# STM32C593 register map
File version: 2.1.0
CPU: CM33 r0p4, little endian, MPU, FPU, 4 interrupt priority bits
Registers are 32-bit, read-write, reset 0x0 unless marked. A register's access mark holds for its fields unless they carry their own. Offsets are from the block's base; [hi:lo] are bit positions; {n}, {i} and the like mark numbered series; 'fields as' and 'values as' point back to an identical list.

## EXTI — EXTI address block description
Base 0x44022000
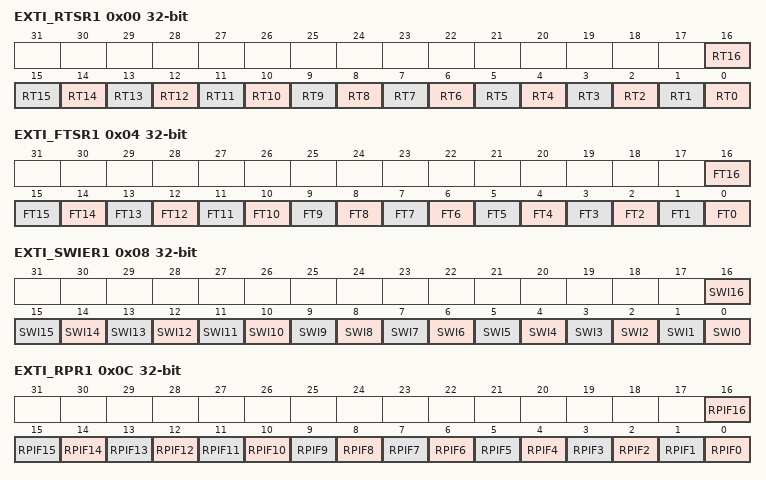
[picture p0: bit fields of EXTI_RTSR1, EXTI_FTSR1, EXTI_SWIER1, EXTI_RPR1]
0x00 EXTI_RTSR1 — EXTI rising trigger selection register
  [all] fields
    0=Rising trigger disabled (for event and interrupt) for input line; 1=Rising trigger enabled (for event and interrupt) for input line
  [n] RT{n} (n=0..16) — Rising trigger event configuration bit of configurable event input x
0x04 EXTI_FTSR1 — EXTI falling trigger selection register
  [all] fields
    0=Falling trigger disabled (for event and Interrupt) for input line; 1=Falling trigger enabled (for event and Interrupt) for input line
  [n] FT{n} (n=0..16) — Falling trigger event configuration bit of configurable event input x
0x08 EXTI_SWIER1 — EXTI software interrupt event register
  [all] fields
    0=Writing 0 has no effect; 1=Writing 1 triggers a rising edge event on event x
  [n] SWI{n} (n=0..16) — Software interrupt on event x
0x0C EXTI_RPR1 — EXTI rising edge pending register
  [all] fields
    0=No rising edge trigger request occurred; 1=Rising edge trigger request occurred
  [n] RPIF{n} (n=0..16) — configurable event inputs x rising edge pending bit
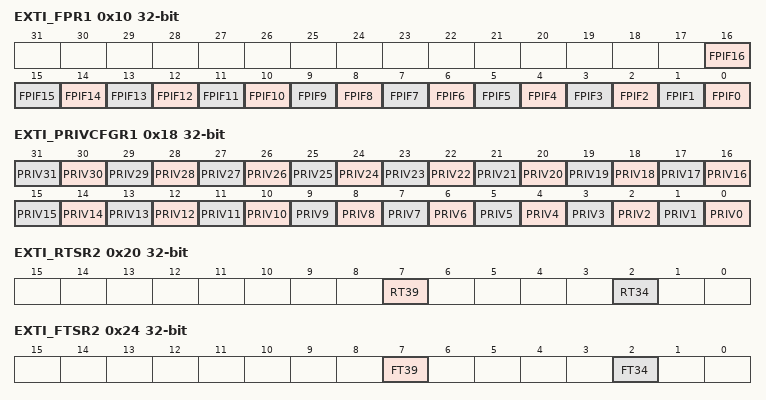
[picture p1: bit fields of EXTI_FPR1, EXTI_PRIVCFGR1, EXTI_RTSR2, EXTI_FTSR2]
0x10 EXTI_FPR1 — EXTI falling edge pending register
  [all] fields
    0=No falling edge trigger request occurred; 1=Falling edge trigger request occurred
  [n] FPIF{n} (n=0..16) — configurable event inputs x falling edge pending bit
0x18 EXTI_PRIVCFGR1 — EXTI privilege configuration register
  [all] fields
    0=Event privilege disabled (unprivileged); 1=Event privilege enabled (privileged)
  [n] PRIV{n} (n=0..31) — Privilege enable on event input x
0x20 EXTI_RTSR2 — EXTI rising trigger selection register 2
  [7] RT39 — Rising trigger event configuration bit of configurable event input 39
    values as the fields of EXTI_RTSR1
  [2] RT34 — Rising trigger event configuration bit of configurable event input 34
    values as the fields of EXTI_RTSR1
0x24 EXTI_FTSR2 — EXTI falling trigger selection register 2
  [7] FT39 — Falling trigger event configuration bit of configurable event input 39
    values as the fields of EXTI_FTSR1
  [2] FT34 — Falling trigger event configuration bit of configurable event input 34
    values as the fields of EXTI_FTSR1
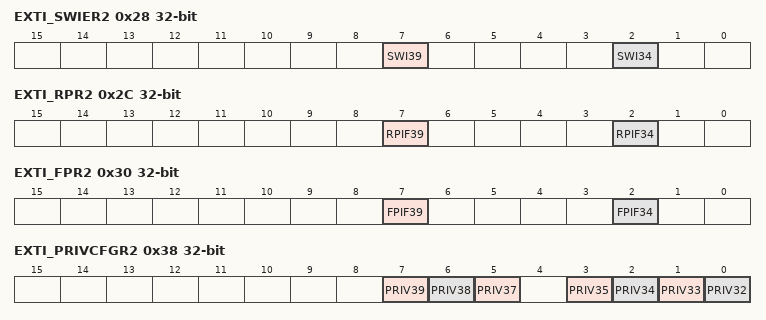
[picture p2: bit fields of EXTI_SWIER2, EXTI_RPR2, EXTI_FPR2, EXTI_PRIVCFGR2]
0x28 EXTI_SWIER2 — EXTI software interrupt event register 2
  [7] SWI39 — Software interrupt on event 39
    0=Writing 0 has no effect; 1=Writing 1 triggers a rising edge event on event 34
  [2] SWI34 — Software interrupt on event 34
    values as SWI39
0x2C EXTI_RPR2 — EXTI rising edge pending register 2
  [7] RPIF39 — configurable event inputs 39 rising edge pending bit
    values as the fields of EXTI_RPR1
  [2] RPIF34 — configurable event inputs 34 rising edge pending bit
    values as the fields of EXTI_RPR1
0x30 EXTI_FPR2 — EXTI falling edge pending register 2
  [7] FPIF39 — configurable event inputs x falling edge pending bit
    values as the fields of EXTI_FPR1
  [2] FPIF34 — configurable event inputs x falling edge pending bit
    values as the fields of EXTI_FPR1
0x38 EXTI_PRIVCFGR2 — EXTI privilege configuration register 2
  [all] fields
    values as the fields of EXTI_PRIVCFGR1
  [7] PRIV39 — Privilege enable on event input x
  [6] PRIV38 — Privilege enable on event input x
  [5] PRIV37 — Privilege enable on event input x
  [n-32] PRIV{n} (n=32..35) — Privilege enable on event input x
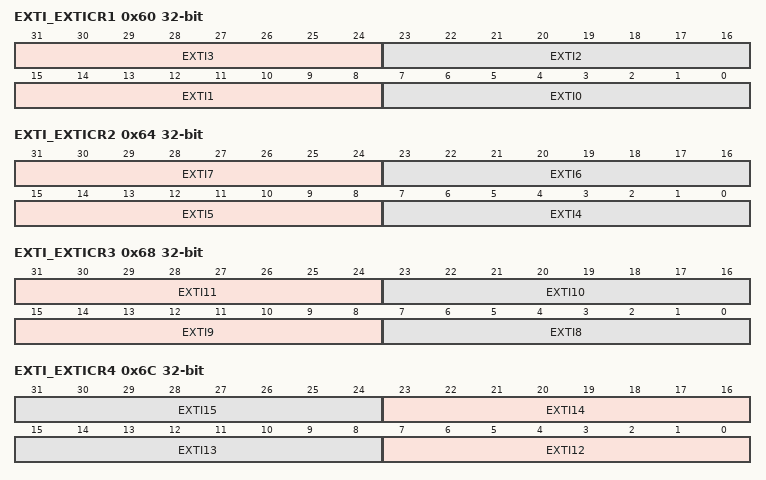
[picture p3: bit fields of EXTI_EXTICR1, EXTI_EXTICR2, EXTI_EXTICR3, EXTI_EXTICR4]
0x60 EXTI_EXTICR1 — EXTI external interrupt selection register
  [31:24] EXTI3 — EXTI3 GPIO port selectio
    0=PA[3] pin; 1=PB[3] pin; 2=PC[3] pin; 3=PD[3] pin; 4=PE[3] pin; 7=PH[3] pin
  [23:16] EXTI2 — EXTI2 GPIO port selection
    0=PA[2] pin; 1=PB[2] pin; 2=PC[2] pin; 3=PD[2] pin; 4=PE[2] pin; 7=PH[2] pin
  [15:8] EXTI1 — EXTI1 GPIO port selection
    0=PA[1] pin; 1=PB[1] pin; 2=PC[1] pin; 3=PD[1] pin; 4=PE[1] pin; 7=PH[1] pin
  [7:0] EXTI0 — EXTI0 GPIO port selection
    0=PA[0] pin; 1=PB[0] pin; 2=PC[0] pin; 3=PD[0] pin; 4=PE[0] pin; 7=PH[0] pin
0x64 EXTI_EXTICR2 — EXTI external interrupt selection register
  [31:24] EXTI7 — EXTI7 GPIO port selection
    0=PA[7] pin; 1=PB[7] pin; 2=PC[7] pin; 3=PD[7] pin; 4=PE[7] pin
  [23:16] EXTI6 — EXTI6 GPIO port selection
    0=PA[6] pin; 1=PB[6] pin; 2=PC[6] pin; 3=PD[6] pin; 4=PE[6] pin
  [15:8] EXTI5 — EXTI5 GPIO port selection
    0=PA[5] pin; 1=PB[5] pin; 2=PC[5] pin; 3=PD[5] pin; 4=PE[5] pin; 7=PH[5] pin
  [7:0] EXTI4 — EXTI4 GPIO port selection
    0=PA[4] pin; 1=PB[4] pin; 2=PC[4] pin; 3=PD[4] pin; 4=PE[4] pin; 7=PH[4] pin
0x68 EXTI_EXTICR3 — EXTI external interrupt selection register
  [31:24] EXTI11 — EXTI11 GPIO port selection
    0=PA[11] pin; 2=PC[11] pin; 3=PD[11] pin; 4=PE[11] pin
  [23:16] EXTI10 — EXTI10 GPIO port selection
    0=PA[10] pin; 1=PB[10] pin; 2=PC[10] pin; 3=PD[10] pin; 4=PE[10] pin
  [15:8] EXTI9 — EXTI9 GPIO port selection
    0=PA[9] pin; 1=PB[9] pin; 2=PC[9] pin; 3=PD[9] pin; 4=PE[9] pin
  [7:0] EXTI8 — EXTI8 GPIO port selection
    0=PA[8] pin; 1=PB[8] pin; 2=PC[8] pin; 3=PD[8] pin; 4=PE[8] pin
0x6C EXTI_EXTICR4 — EXTI external interrupt selection register
  [8n-89:8n-96] EXTI{n} (n=12..15) — EXTI{n} GPIO port selection
    0=PA[{n}] pin; 1=PB[{n}] pin; 2=PC[{n}] pin; 3=PD[{n}] pin; 4=PE[{n}] pin
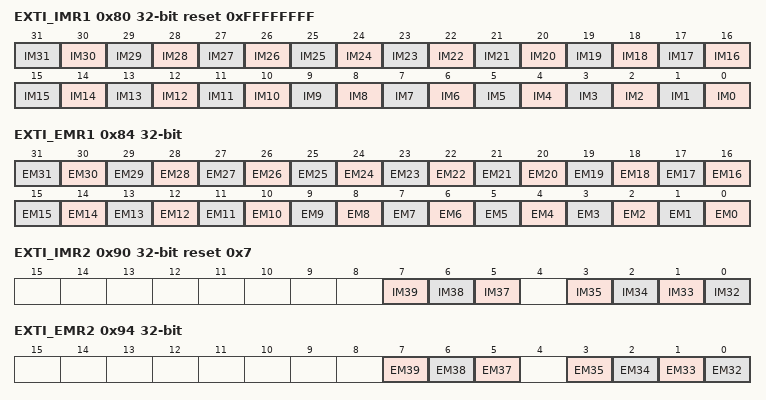
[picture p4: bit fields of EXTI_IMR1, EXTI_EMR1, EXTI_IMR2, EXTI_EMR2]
0x80 EXTI_IMR1 reset 0xFFFFFFFF — EXTI CPU wakeup with interrupt mask register
  [all] fields
    0=Wakeup with interrupt request from input event x is masked; 1=Wakeup with interrupt request from input event x is unmasked
  [n] IM{n} (n=0..31) — CPU wakeup with interrupt mask on event input x
0x84 EXTI_EMR1 — EXTI CPU wakeup with event mask register
  [all] fields
    0=Wakeup with event generation from Line x is masked; 1=Wakeup with event generation from Line x is unmasked
  [n] EM{n} (n=0..31) — CPU wakeup with event generation mask on event input x
0x90 EXTI_IMR2 reset 0x7 — EXTI CPU wakeup with interrupt mask register 2
  [all] fields
    values as the fields of EXTI_IMR1
  [7] IM39 — CPU wakeup with interrupt mask on event input x less thansup>(1)less than/sup>
  [6] IM38 — CPU wakeup with interrupt mask on event input x less thansup>(1)less than/sup>
  [5] IM37 — CPU wakeup with interrupt mask on event input x less thansup>(1)less than/sup>
  [n-32] IM{n} (n=32..35) — CPU wakeup with interrupt mask on event input x less thansup>(1)less than/sup>
0x94 EXTI_EMR2 — EXTI CPU wakeup with event mask register 2
  [all] fields
    values as the fields of EXTI_EMR1
  [7] EM39 — CPU wakeup with event generation mask on event input x
  [6] EM38 — CPU wakeup with event generation mask on event input x
  [5] EM37 — CPU wakeup with event generation mask on event input x
  [n-32] EM{n} (n=32..35) — CPU wakeup with event generation mask on event input x
